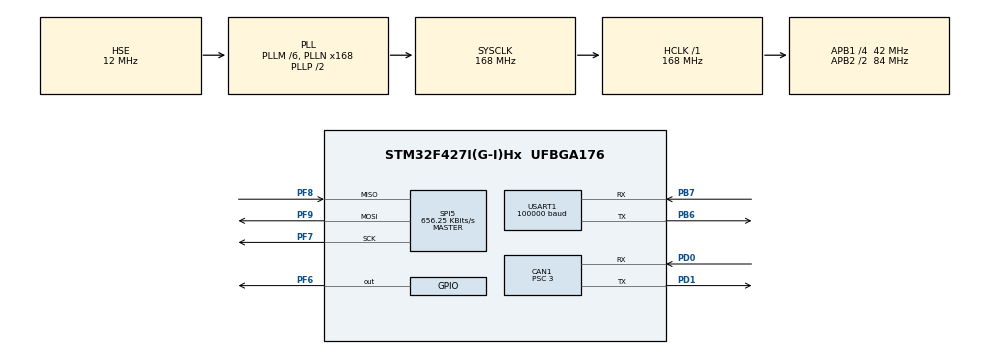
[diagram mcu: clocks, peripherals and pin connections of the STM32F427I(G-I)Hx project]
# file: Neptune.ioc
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CAN1.BS1=CAN_BS1_12TQ
CAN1.CalculateBaudRate=1000000
CAN1.CalculateTimeBit=1000
CAN1.CalculateTimeQuantum=71.42857142857143
CAN1.Prescaler=3
Dma.Request0=USART1_RX
Dma.Request1=SPI5_RX
Dma.SPI5_RX.1.Direction=DMA_PERIPH_TO_MEMORY
Dma.SPI5_RX.1.FIFOMode=DMA_FIFOMODE_DISABLE
Dma.SPI5_RX.1.Instance=DMA2_Stream3
Dma.SPI5_RX.1.MemDataAlignment=DMA_MDATAALIGN_BYTE
Dma.SPI5_RX.1.MemInc=DMA_MINC_ENABLE
Dma.SPI5_RX.1.Mode=DMA_NORMAL
Dma.SPI5_RX.1.PeriphDataAlignment=DMA_PDATAALIGN_BYTE
Dma.SPI5_RX.1.PeriphInc=DMA_PINC_DISABLE
Dma.SPI5_RX.1.Priority=DMA_PRIORITY_LOW
Dma.USART1_RX.0.Direction=DMA_PERIPH_TO_MEMORY
Dma.USART1_RX.0.FIFOMode=DMA_FIFOMODE_DISABLE
Dma.USART1_RX.0.Instance=DMA2_Stream2
Dma.USART1_RX.0.MemDataAlignment=DMA_MDATAALIGN_BYTE
Dma.USART1_RX.0.MemInc=DMA_MINC_ENABLE
Dma.USART1_RX.0.Mode=DMA_NORMAL
Dma.USART1_RX.0.PeriphDataAlignment=DMA_PDATAALIGN_BYTE
Dma.USART1_RX.0.PeriphInc=DMA_PINC_DISABLE
Dma.USART1_RX.0.Priority=DMA_PRIORITY_LOW
Mcu.Family=STM32F4
Mcu.Name=STM32F427I(G-I)Hx
Mcu.Package=UFBGA176
NVIC.CAN1_RX0_IRQn=true\:0\:0\:false\:false\:true\:true\:true\:true
NVIC.DMA2_Stream2_IRQn=true\:0\:0\:true\:false\:true\:false\:true\:true
NVIC.DMA2_Stream3_IRQn=true\:0\:0\:false\:false\:true\:false\:true\:true
NVIC.PriorityGroup=NVIC_PRIORITYGROUP_4
NVIC.SPI5_IRQn=true\:0\:0\:false\:false\:true\:true\:true\:true
NVIC.TIM2_IRQn=true\:0\:0\:false\:false\:true\:true\:true\:true
NVIC.USART1_IRQn=true\:0\:0\:false\:false\:true\:true\:true\:true
PA13.Mode=Serial_Wire
PA13.Signal=SYS_JTMS-SWDIO
PA14.Mode=Serial_Wire
PA14.Signal=SYS_JTCK-SWCLK
PB6.Mode=Asynchronous
PB6.Signal=USART1_TX
PB7.Mode=Asynchronous
PB7.Signal=USART1_RX
PD0.Mode=CAN_Activate
PD0.Signal=CAN1_RX
PD1.Mode=CAN_Activate
PD1.Signal=CAN1_TX
PF6.Signal=GPIO_Output
PF7.Mode=Full_Duplex_Master
PF7.Signal=SPI5_SCK
PF8.Mode=Full_Duplex_Master
PF8.Signal=SPI5_MISO
PF9.Mode=Full_Duplex_Master
PF9.Signal=SPI5_MOSI
PH0/OSC_IN.Mode=HSE-External-Oscillator
PH0/OSC_IN.Signal=RCC_OSC_IN
PH1/OSC_OUT.Mode=HSE-External-Oscillator
PH1/OSC_OUT.Signal=RCC_OSC_OUT
ProjectManager.HeapSize=0x200
ProjectManager.StackSize=0x400
ProjectManager.TargetToolchain=MDK-ARM V5.32
RCC.48MHZClocksFreq_Value=84000000
RCC.AHBFreq_Value=168000000
RCC.APB1CLKDivider=RCC_HCLK_DIV4
RCC.APB1Freq_Value=42000000
RCC.APB1TimFreq_Value=84000000
RCC.APB2CLKDivider=RCC_HCLK_DIV2
RCC.APB2Freq_Value=84000000
RCC.APB2TimFreq_Value=168000000
RCC.CortexFreq_Value=168000000
RCC.HCLKFreq_Value=168000000
RCC.HSE_VALUE=12000000
RCC.HSI_VALUE=16000000
RCC.LSE_VALUE=32768
RCC.PLLM=6
RCC.PLLN=168
RCC.PLLSourceVirtual=RCC_PLLSOURCE_HSE
RCC.SYSCLKFreq_VALUE=168000000
RCC.SYSCLKSource=RCC_SYSCLKSOURCE_PLLCLK
RCC.VCOOutputFreq_Value=336000000
SPI5.BaudRatePrescaler=SPI_BAUDRATEPRESCALER_128
SPI5.CLKPhase=SPI_PHASE_2EDGE
SPI5.CLKPolarity=SPI_POLARITY_HIGH
SPI5.CalculateBaudRate=656.25 KBits/s
SPI5.Direction=SPI_DIRECTION_2LINES
SPI5.Mode=SPI_MODE_MASTER
SPI5.VirtualType=VM_MASTER
TIM2.Period=9
TIM2.Prescaler=8399
USART1.BaudRate=100000
USART1.Parity=PARITY_EVEN
USART1.VirtualMode=VM_ASYNC
USART1.WordLength=WORDLENGTH_9B
VP_TIM2_VS_ClockSourceINT.Mode=Internal
board=custom

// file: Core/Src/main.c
/* USER CODE BEGIN Header */
/**
  ******************************************************************************
  * @file           : main.c
  * @brief          : Main program body
  ******************************************************************************
  * @attention
  *
  * Copyright (c) 2024 STMicroelectronics.
  * All rights reserved.
  *
  * This software is licensed under terms that can be found in the LICENSE file
  * in the root directory of this software component.
  * If no LICENSE file comes with this software, it is provided AS-IS.
  *
  ******************************************************************************
  */
/* USER CODE END Header */
#include "main.h"

/* USER CODE BEGIN Includes */

#include "rc.h"
#include "imu.h"
#include "system.h"
#include "mes.h"
#include "pid.h"
//#include "spi.h"

/* USER CODE END Includes */

CAN_HandleTypeDef hcan1;

SPI_HandleTypeDef hspi5;
DMA_HandleTypeDef hdma_spi5_rx;

TIM_HandleTypeDef htim2;

UART_HandleTypeDef huart1;
DMA_HandleTypeDef hdma_usart1_rx;

void SystemClock_Config(void);
static void MX_GPIO_Init(void);
static void MX_DMA_Init(void);
static void MX_USART1_UART_Init(void);
static void MX_SPI5_Init(void);
static void MX_CAN1_Init(void);
static void MX_TIM2_Init(void);

/* USER CODE BEGIN 0 */
/*void can_filter_init(void)
{

    CAN_FilterTypeDef can_filter_st;
    can_filter_st.FilterActivation = ENABLE;
    can_filter_st.FilterMode = CAN_FILTERMODE_IDMASK;
    can_filter_st.FilterScale = CAN_FILTERSCALE_32BIT;
    can_filter_st.FilterIdHigh = 0x0000;
    can_filter_st.FilterIdLow = 0x0000;
    can_filter_st.FilterMaskIdHigh = 0x0000;
    can_filter_st.FilterMaskIdLow = 0x0000;
    can_filter_st.FilterBank = 0;
    can_filter_st.FilterFIFOAssignment = CAN_RX_FIFO0;
    HAL_CAN_ConfigFilter(&hcan1, &can_filter_st);
    HAL_CAN_Start(&hcan1);
    HAL_CAN_ActivateNotification(&hcan1, CAN_IT_RX_FIFO0_MSG_PENDING);
}*/

int count1 = 0;
int stopt = 1;
/* USER CODE END 0 */

int main(void)
{

  /* MCU Configuration--------------------------------------------------------*/

  /* Reset of all peripherals, Initializes the Flash interface and the Systick. */
  HAL_Init();

  /* Configure the system clock */
  SystemClock_Config();

  /* Initialize all configured peripherals */
  MX_GPIO_Init();
  MX_DMA_Init();
  MX_USART1_UART_Init();
  MX_SPI5_Init();
  MX_CAN1_Init();
  MX_TIM2_Init();
  /* USER CODE BEGIN 2 */
	/*rc_init(&huart1);
	imu_init();*/

	//1
	//can_filter_init();
  //HAL_TIM_Base_Start_IT(&htim2);

	//mpu_device_init();

//	PID_t pid1;

	//PID_Init(&pid1, 40, 19, 100, 20000.0, 50000, 5000);

	//system_init(&huart1, &hspi5, &hcan1);
	//__HAL_UART_DISABLE_IT(&huart1, UART_IT_RXNE);
	//rc_init(&huart1);

	//2
	//HAL_UARTEx_ReceiveToIdle_DMA(&huart1, rxBuffer1, RX_BUFFER_SIZE);
	//PID_Init(&pid1, 60, 19, 100, 20000.0, 20000, 5000);
	//PID_Init(&pid2, 60, 19, 100, 20000.0, 20000, 5000);
	//PID_Init(&pid3, 60, 19, 100, 20000.0, 20000, 5000);
	//PID_Init(&pid4, 60, 19, 100, 20000.0, 20000, 5000);
	//PID_Init(&pos, 40, 0, 400, 20000.0, 1800, 1800);

	//__HAL_UART_DISABLE_IT(&huart1, UART_IT_RXNE);
	//imu_init();

	//3
	//mpu_device_init();

	//__HAL_UART_DISABLE_IT(&huart1, UART_IT_RXNE);
	//__HAL_UART_DISABLE_IT(&huart1, UART_IT_RXNE);
	system_init(&huart1, &hspi5, &hcan1, &htim2);
  /* USER CODE END 2 */

  /* Infinite loop */
  /* USER CODE BEGIN WHILE */
  while (1)
  {
		mpu_get_data();
		//system_loop();
    /* USER CODE END WHILE */

  }
}

void SystemClock_Config(void)
{
  RCC_OscInitTypeDef RCC_OscInitStruct = {0};
  RCC_ClkInitTypeDef RCC_ClkInitStruct = {0};

  /** Configure the main internal regulator output voltage
  */
  __HAL_RCC_PWR_CLK_ENABLE();
  __HAL_PWR_VOLTAGESCALING_CONFIG(PWR_REGULATOR_VOLTAGE_SCALE1);

  /** Initializes the RCC Oscillators according to the specified parameters
  * in the RCC_OscInitTypeDef structure.
  */
  RCC_OscInitStruct.OscillatorType = RCC_OSCILLATORTYPE_HSE;
  RCC_OscInitStruct.HSEState = RCC_HSE_ON;
  RCC_OscInitStruct.PLL.PLLState = RCC_PLL_ON;
  RCC_OscInitStruct.PLL.PLLSource = RCC_PLLSOURCE_HSE;
  RCC_OscInitStruct.PLL.PLLM = 6;
  RCC_OscInitStruct.PLL.PLLN = 168;
  RCC_OscInitStruct.PLL.PLLP = RCC_PLLP_DIV2;
  RCC_OscInitStruct.PLL.PLLQ = 4;
  if (HAL_RCC_OscConfig(&RCC_OscInitStruct) != HAL_OK)
  {
    Error_Handler();
  }

  /** Initializes the CPU, AHB and APB buses clocks
  */
  RCC_ClkInitStruct.ClockType = RCC_CLOCKTYPE_HCLK|RCC_CLOCKTYPE_SYSCLK
                              |RCC_CLOCKTYPE_PCLK1|RCC_CLOCKTYPE_PCLK2;
  RCC_ClkInitStruct.SYSCLKSource = RCC_SYSCLKSOURCE_PLLCLK;
  RCC_ClkInitStruct.AHBCLKDivider = RCC_SYSCLK_DIV1;
  RCC_ClkInitStruct.APB1CLKDivider = RCC_HCLK_DIV4;
  RCC_ClkInitStruct.APB2CLKDivider = RCC_HCLK_DIV2;

  if (HAL_RCC_ClockConfig(&RCC_ClkInitStruct, FLASH_LATENCY_5) != HAL_OK)
  {
    Error_Handler();
  }
}

static void MX_CAN1_Init(void)
{

  hcan1.Instance = CAN1;
  hcan1.Init.Prescaler = 3;
  hcan1.Init.Mode = CAN_MODE_NORMAL;
  hcan1.Init.SyncJumpWidth = CAN_SJW_1TQ;
  hcan1.Init.TimeSeg1 = CAN_BS1_12TQ;
  hcan1.Init.TimeSeg2 = CAN_BS2_1TQ;
  hcan1.Init.TimeTriggeredMode = DISABLE;
  hcan1.Init.AutoBusOff = DISABLE;
  hcan1.Init.AutoWakeUp = DISABLE;
  hcan1.Init.AutoRetransmission = DISABLE;
  hcan1.Init.ReceiveFifoLocked = DISABLE;
  hcan1.Init.TransmitFifoPriority = DISABLE;
  if (HAL_CAN_Init(&hcan1) != HAL_OK)
  {
    Error_Handler();
  }

}

static void MX_SPI5_Init(void)
{

  /* SPI5 parameter configuration*/
  hspi5.Instance = SPI5;
  hspi5.Init.Mode = SPI_MODE_MASTER;
  hspi5.Init.Direction = SPI_DIRECTION_2LINES;
  hspi5.Init.DataSize = SPI_DATASIZE_8BIT;
  hspi5.Init.CLKPolarity = SPI_POLARITY_HIGH;
  hspi5.Init.CLKPhase = SPI_PHASE_2EDGE;
  hspi5.Init.NSS = SPI_NSS_SOFT;
  hspi5.Init.BaudRatePrescaler = SPI_BAUDRATEPRESCALER_128;
  hspi5.Init.FirstBit = SPI_FIRSTBIT_MSB;
  hspi5.Init.TIMode = SPI_TIMODE_DISABLE;
  hspi5.Init.CRCCalculation = SPI_CRCCALCULATION_DISABLE;
  hspi5.Init.CRCPolynomial = 10;
  if (HAL_SPI_Init(&hspi5) != HAL_OK)
  {
    Error_Handler();
  }

}

static void MX_TIM2_Init(void)
{

  TIM_ClockConfigTypeDef sClockSourceConfig = {0};
  TIM_MasterConfigTypeDef sMasterConfig = {0};

  htim2.Instance = TIM2;
  htim2.Init.Prescaler = 8399;
  htim2.Init.CounterMode = TIM_COUNTERMODE_UP;
  htim2.Init.Period = 9;
  htim2.Init.ClockDivision = TIM_CLOCKDIVISION_DIV1;
  htim2.Init.AutoReloadPreload = TIM_AUTORELOAD_PRELOAD_DISABLE;
  if (HAL_TIM_Base_Init(&htim2) != HAL_OK)
  {
    Error_Handler();
  }
  sClockSourceConfig.ClockSource = TIM_CLOCKSOURCE_INTERNAL;
  if (HAL_TIM_ConfigClockSource(&htim2, &sClockSourceConfig) != HAL_OK)
  {
    Error_Handler();
  }
  sMasterConfig.MasterOutputTrigger = TIM_TRGO_RESET;
  sMasterConfig.MasterSlaveMode = TIM_MASTERSLAVEMODE_DISABLE;
  if (HAL_TIMEx_MasterConfigSynchronization(&htim2, &sMasterConfig) != HAL_OK)
  {
    Error_Handler();
  }

}

static void MX_USART1_UART_Init(void)
{

  huart1.Instance = USART1;
  huart1.Init.BaudRate = 100000;
  huart1.Init.WordLength = UART_WORDLENGTH_9B;
  huart1.Init.StopBits = UART_STOPBITS_1;
  huart1.Init.Parity = UART_PARITY_EVEN;
  huart1.Init.Mode = UART_MODE_TX_RX;
  huart1.Init.HwFlowCtl = UART_HWCONTROL_NONE;
  huart1.Init.OverSampling = UART_OVERSAMPLING_16;
  if (HAL_UART_Init(&huart1) != HAL_OK)
  {
    Error_Handler();
  }

}

static void MX_DMA_Init(void)
{

  /* DMA controller clock enable */
  __HAL_RCC_DMA2_CLK_ENABLE();

  /* DMA interrupt init */
  /* DMA2_Stream2_IRQn interrupt configuration */
  HAL_NVIC_SetPriority(DMA2_Stream2_IRQn, 0, 0);
  HAL_NVIC_EnableIRQ(DMA2_Stream2_IRQn);
  /* DMA2_Stream3_IRQn interrupt configuration */
  HAL_NVIC_SetPriority(DMA2_Stream3_IRQn, 0, 0);
  HAL_NVIC_EnableIRQ(DMA2_Stream3_IRQn);

}

static void MX_GPIO_Init(void)
{
  GPIO_InitTypeDef GPIO_InitStruct = {0};

  /* GPIO Ports Clock Enable */
  __HAL_RCC_GPIOA_CLK_ENABLE();
  __HAL_RCC_GPIOB_CLK_ENABLE();
  __HAL_RCC_GPIOD_CLK_ENABLE();
  __HAL_RCC_GPIOH_CLK_ENABLE();
  __HAL_RCC_GPIOF_CLK_ENABLE();

  /*Configure GPIO pin Output Level */
  HAL_GPIO_WritePin(GPIOF, GPIO_PIN_6, GPIO_PIN_RESET);

  /*Configure GPIO pin : PF6 */
  GPIO_InitStruct.Pin = GPIO_PIN_6;
  GPIO_InitStruct.Mode = GPIO_MODE_OUTPUT_PP;
  GPIO_InitStruct.Pull = GPIO_NOPULL;
  GPIO_InitStruct.Speed = GPIO_SPEED_FREQ_LOW;
  HAL_GPIO_Init(GPIOF, &GPIO_InitStruct);

}

void Error_Handler(void)
{
  __disable_irq();
  while (1)
  {
  }
}
